# ESP32-H4 register map
Vendor: ESPRESSIF SYSTEMS (SHANGHAI) CO., LTD.; Series: ESP32 H-Series; File version: 1
CPU: RV32IMAC r0p0, little endian, no MPU, no FPU, 0 interrupt priority bits
Address unit: 32 bits
Registers are 32-bit, read-write, reset 0x0 unless marked. A register's access mark holds for its fields unless they carry their own. Offsets are from the block's base; [hi:lo] are bit positions; {n}, {i} and the like mark numbered series.

## RNG — Hardware Random Number Generator
Base 0x600B2000
0x00 DATA ro — RNG result register
  [31:0] RND_DATA — get rng data
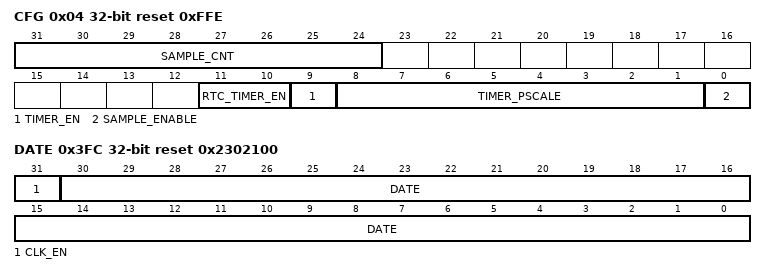
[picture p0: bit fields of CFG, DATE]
0x04 CFG access per field reset 0xFFE — configure rng register
  [31:24] SAMPLE_CNT ro — reserved
  [11:10] RTC_TIMER_EN rw — reserved
  [9] TIMER_EN rw — enable rng xor async rng timer
  [8:1] TIMER_PSCALE rw — configure rng timer clk div
  [0] SAMPLE_ENABLE rw — reserved
0x08 DATA_SYNC ro — rng result sync register
  [31:0] RND_SYNC_DATA — get rnd sync result
0x3FC DATE reset 0x2302100
  [31] CLK_EN — force on reg clk
  [30:0] DATE — RNG date information/ RNG version information.

## SHA — SHA (Secure Hash Algorithm) Accelerator
Base 0x600A7000
0x00 MODE reset 0x2 — Configures SHA algorithm
  [3:0] MODE — Configures the SHA algorithm. \\ 0: SHA-1\\ 1: SHA2-224\\ 2: SHA2-256\\ 3: SHA2-384\\ 4: SHA2-512\\ 5: SHA2-512/224\\ 6: SHA2-512/256\\ 7: SHA2-512/t\\ 8: SHA3-224\\ 9: SHA3-256\\ 10: SHA3-384\\ 11: SHA3-512\\ 12: SHAKE128\\ 13: SHAKE256\\ 14: SM3\\
0x04 T_STRING — SHA 512/t configuration register 0.
  [31:0] T_STRING — Sha t_string (used if and only if mode == SHA_512/t).
0x08 T_LENGTH — SHA 512/t configuration register 1.
  [6:0] T_LENGTH — Sha t_length (used if and only if mode == SHA_512/t).
0x0C DMA_BLOCK_NUM — Block number register (only effective for DMA-SHA)
  [15:0] DMA_BLOCK_NUM — Configures the DMA-SHA block number.
0x10 START wo — Starts the SHA accelerator for Typical SHA operation
  [0] START — Start typical sha.
0x14 CONTINUE wo — Continues SHA operation (only effective in Typical SHA mode)
  [0] CONTINUE — Continue typical sha.
0x18 BUSY ro — Represents if SHA Accelerator is busy or not
  [0] STATE — Represents the states of SHA accelerator. \\ 0: idle\\ 1: busy\\
0x1C DMA_START wo — Starts the SHA accelerator for DMA-SHA operation
  [0] DMA_START — Write 1 to start DMA-SHA calculation.
0x20 DMA_CONTINUE wo — Continues SHA operation (only effective in DMA-SHA mode)
  [0] DMA_CONTINUE — Write 1 to continue DMA-SHA calculation.
0x24 CLEAR_IRQ wo — DMA-SHA interrupt clear register
  [0] CLEAR_INTERRUPT — Write 1 to clear DMA-SHA interrupt.
0x28 IRQ_ENA — DMA-SHA interrupt enable register
  [0] INTERRUPT_ENA — Write 1 to enable DMA-SHA interrupt.
0x2C DATE reset 0x20240823 — Version control register
  [29:0] DATE — Version control register.
0x30 DMA_RX_RESET wo — DMA RX FIFO Reset Signal
  [0] DMA_RX_RESET — Write 1 to reset DMA RX FIFO
{0x40+i} _2_SM_3_H_MEM[{i}] (i=0..63) 8-bit access not given — SHA1, SHA2-256, SM3 H memory which contains intermediate hash or final hash. \\ SHA1, SHA2-256, SM3 : 0x00~0x20 (R/W) \\ SHA2-512 : 0x00~0x40 (R/W) \\
{0x80+i} _2_SM_3_M_MEM[{i}] (i=0..127) 8-bit access not given — SHA1, SHA2-256, SM3 M memory which contains message. \\ SHA1, SHA2-256, SM3 : 0x00~0x40 \\ SHA2-512 : 0x00~0x80 \\

## TOUCH — TOUCH Peripheral
Base 0x600B5800
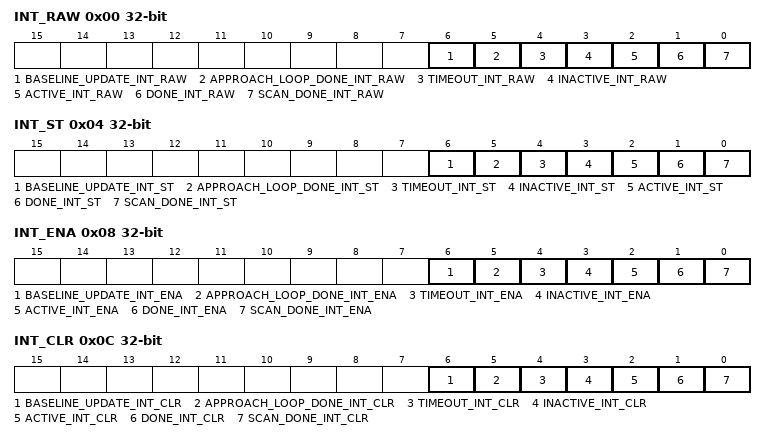
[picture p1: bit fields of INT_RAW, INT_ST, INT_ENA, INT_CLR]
0x00 INT_RAW — need_des
  [6] BASELINE_UPDATE_INT_RAW — need_des
  [5] APPROACH_LOOP_DONE_INT_RAW — need_des
  [4] TIMEOUT_INT_RAW — need_des
  [3] INACTIVE_INT_RAW — need_des
  [2] ACTIVE_INT_RAW — need_des
  [1] DONE_INT_RAW — need_des
  [0] SCAN_DONE_INT_RAW — need_des
0x04 INT_ST ro — need_des
  [6] BASELINE_UPDATE_INT_ST — need_des
  [5] APPROACH_LOOP_DONE_INT_ST — need_des
  [4] TIMEOUT_INT_ST — need_des
  [3] INACTIVE_INT_ST — need_des
  [2] ACTIVE_INT_ST — need_des
  [1] DONE_INT_ST — need_des
  [0] SCAN_DONE_INT_ST — need_des
0x08 INT_ENA — need_des
  [6] BASELINE_UPDATE_INT_ENA — need_des
  [5] APPROACH_LOOP_DONE_INT_ENA — need_des
  [4] TIMEOUT_INT_ENA — need_des
  [3] INACTIVE_INT_ENA — need_des
  [2] ACTIVE_INT_ENA — need_des
  [1] DONE_INT_ENA — need_des
  [0] SCAN_DONE_INT_ENA — need_des
0x0C INT_CLR wo — need_des
  [6] BASELINE_UPDATE_INT_CLR — need_des
  [5] APPROACH_LOOP_DONE_INT_CLR — need_des
  [4] TIMEOUT_INT_CLR — need_des
  [3] INACTIVE_INT_CLR — need_des
  [2] ACTIVE_INT_CLR — need_des
  [1] DONE_INT_CLR — need_des
  [0] SCAN_DONE_INT_CLR — need_des
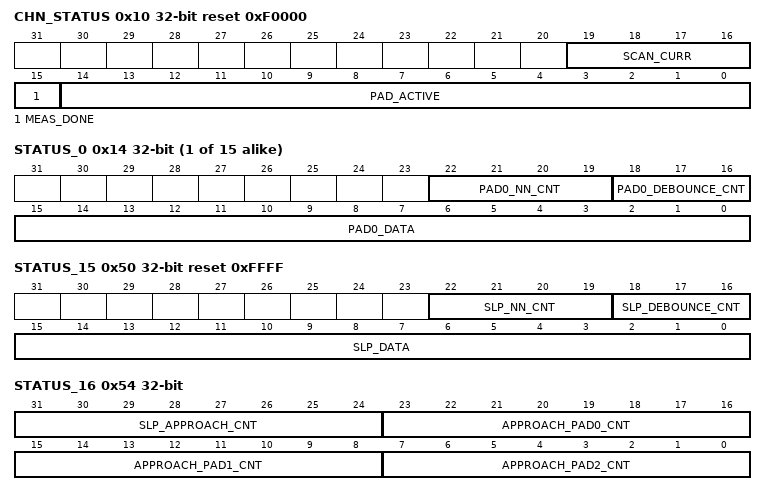
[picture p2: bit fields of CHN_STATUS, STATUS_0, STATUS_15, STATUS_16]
0x10 CHN_STATUS ro reset 0xF0000 — need_des
  [19:16] SCAN_CURR — need_des
  [15] MEAS_DONE — need_des
  [14:0] PAD_ACTIVE — need_des
{0x14+4i} STATUS_{i} ro (i=0..14) — need_des
  [22:19] PAD{i}_NN_CNT — need_des
  [18:16] PAD{i}_DEBOUNCE_CNT — need_des
  [15:0] PAD{i}_DATA — need_des
0x50 STATUS_15 ro reset 0xFFFF — need_des
  [22:19] SLP_NN_CNT — need_des
  [18:16] SLP_DEBOUNCE_CNT — need_des
  [15:0] SLP_DATA — need_des
0x54 STATUS_16 ro — need_des
  [31:24] SLP_APPROACH_CNT — need_des
  [23:16] APPROACH_PAD0_CNT — need_des
  [15:8] APPROACH_PAD1_CNT — need_des
  [7:0] APPROACH_PAD2_CNT — need_des
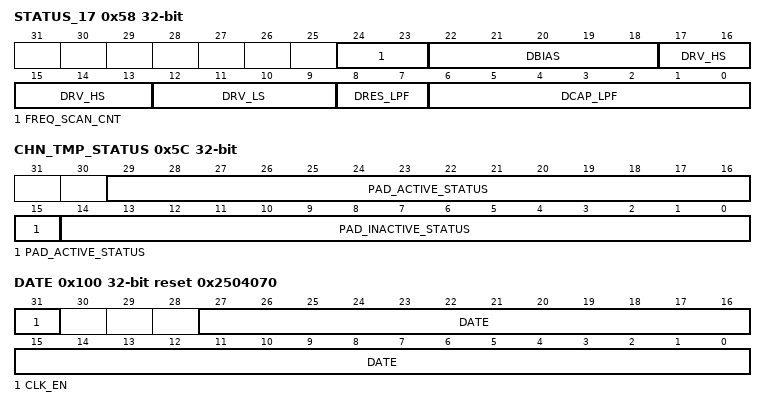
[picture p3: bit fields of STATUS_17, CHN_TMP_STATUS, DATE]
0x58 STATUS_17 ro — need_des
  [24:23] FREQ_SCAN_CNT — need_des
  [22:18] DBIAS — need_des
  [17:13] DRV_HS — need_des
  [12:9] DRV_LS — need_des
  [8:7] DRES_LPF — need_des
  [6:0] DCAP_LPF — Reserved
0x5C CHN_TMP_STATUS ro — need_des
  [29:15] PAD_ACTIVE_STATUS — need_des
  [14:0] PAD_INACTIVE_STATUS — need_des
0x100 DATE reset 0x2504070 — need_des
  [31] CLK_EN — need_des
  [27:0] DATE — need_des

## USB_WRAP — USB_WRAP Peripheral
Base 0x60080000
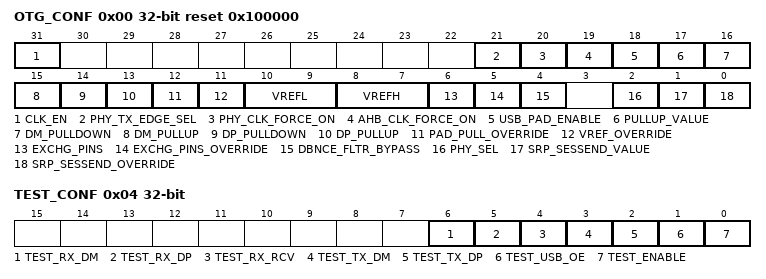
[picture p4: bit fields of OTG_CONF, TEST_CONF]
0x00 OTG_CONF reset 0x100000 — USB wrapper configuration registers.
  [31] CLK_EN — Disable auto clock gating of CSR registers.
  [21] PHY_TX_EDGE_SEL — Select phy tx signal output clock edge. 1'b0: negedge, 1'b1: posedge.
  [20] PHY_CLK_FORCE_ON — Force phy clock always on.
  [19] AHB_CLK_FORCE_ON — Force ahb clock always on.
  [18] USB_PAD_ENABLE — Enable USB pad function.
  [17] PULLUP_VALUE — Controlle pullup value. 1'b0: typical value is 2.4K, 1'b1: typical value is 1.2K.
  [16] DM_PULLDOWN — Controlle USB D+ pulldown.
  [15] DM_PULLUP — Controlle USB D+ pullup.
  [14] DP_PULLDOWN — Controlle USB D+ pulldown.
  [13] DP_PULLUP — Controlle USB D+ pullup.
  [12] PAD_PULL_OVERRIDE — Enable software controlle USB D+ D- pullup pulldown.
  [11] VREF_OVERRIDE — Enable software controlle input threshold.
  [10:9] VREFL — Control single-end input low threshold,0.8V to 1.04V, step 80mV.
  [8:7] VREFH — Control single-end input high threshold,1.76V to 2V, step 80mV.
  [6] EXCHG_PINS — USB D+ D- exchange. 1'b0: don't change, 1'b1: exchange D+ D-.
  [5] EXCHG_PINS_OVERRIDE — Enable software controlle USB D+ D- exchange
  [4] DBNCE_FLTR_BYPASS — Bypass Debounce filters for avalid,bvalid,vbusvalid,session end, id signals
  [2] PHY_SEL — Select internal external PHY. 1'b0: Select internal PHY, 1'b1: Select external PHY.
  [1] SRP_SESSEND_VALUE — Software over-ride value of srp session end signal.
  [0] SRP_SESSEND_OVERRIDE — This bit is used to enable the software over-ride of srp session end signal. 1'b0: the signal is controlled by the chip input, 1'b1: the signal is controlled by the software.
0x04 TEST_CONF access per field — USB wrapper test configuration registers.
  [6] TEST_RX_DM ro — USB D- rx value in test.
  [5] TEST_RX_DP ro — USB D+ rx value in test.
  [4] TEST_RX_RCV ro — USB differential rx value in test.
  [3] TEST_TX_DM rw — USB D- tx value in test.
  [2] TEST_TX_DP rw — USB D+ tx value in test.
  [1] TEST_USB_OE rw — USB pad oen in test.
  [0] TEST_ENABLE rw — Enable test of the USB pad.
0x3FC DATE reset 0x2403200
  [31:0] USB_WRAP_DATE
